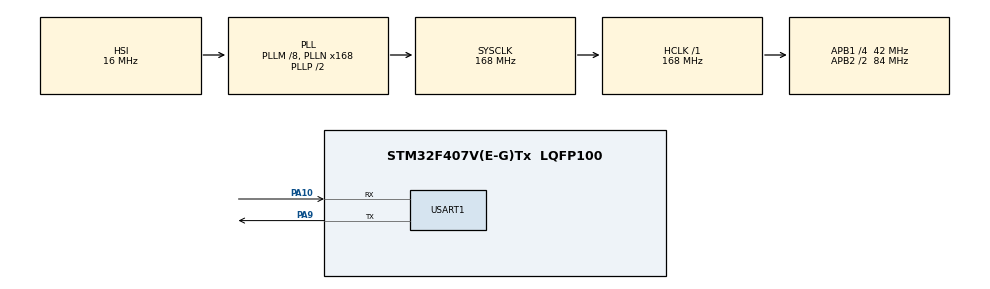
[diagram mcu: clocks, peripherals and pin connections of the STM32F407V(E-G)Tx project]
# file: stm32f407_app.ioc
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Dma.Request0=USART1_RX
Dma.Request1=USART1_TX
Dma.USART1_RX.0.Direction=DMA_PERIPH_TO_MEMORY
Dma.USART1_RX.0.FIFOMode=DMA_FIFOMODE_DISABLE
Dma.USART1_RX.0.Instance=DMA2_Stream2
Dma.USART1_RX.0.MemDataAlignment=DMA_MDATAALIGN_BYTE
Dma.USART1_RX.0.MemInc=DMA_MINC_ENABLE
Dma.USART1_RX.0.Mode=DMA_NORMAL
Dma.USART1_RX.0.PeriphDataAlignment=DMA_PDATAALIGN_BYTE
Dma.USART1_RX.0.PeriphInc=DMA_PINC_DISABLE
Dma.USART1_RX.0.Priority=DMA_PRIORITY_LOW
Dma.USART1_TX.1.Direction=DMA_MEMORY_TO_PERIPH
Dma.USART1_TX.1.FIFOMode=DMA_FIFOMODE_DISABLE
Dma.USART1_TX.1.Instance=DMA2_Stream7
Dma.USART1_TX.1.MemDataAlignment=DMA_MDATAALIGN_BYTE
Dma.USART1_TX.1.MemInc=DMA_MINC_ENABLE
Dma.USART1_TX.1.Mode=DMA_NORMAL
Dma.USART1_TX.1.PeriphDataAlignment=DMA_PDATAALIGN_BYTE
Dma.USART1_TX.1.PeriphInc=DMA_PINC_DISABLE
Dma.USART1_TX.1.Priority=DMA_PRIORITY_LOW
Mcu.Family=STM32F4
Mcu.Name=STM32F407V(E-G)Tx
Mcu.Package=LQFP100
NVIC.DMA2_Stream2_IRQn=true\:0\:0\:false\:false\:true\:false
NVIC.DMA2_Stream7_IRQn=true\:0\:0\:false\:false\:true\:false
NVIC.PriorityGroup=NVIC_PRIORITYGROUP_4
NVIC.USART1_IRQn=true\:0\:0\:false\:false\:true\:true
PA10.Mode=Asynchronous
PA10.Signal=USART1_RX
PA9.Mode=Asynchronous
PA9.Signal=USART1_TX
ProjectManager.HeapSize=0x200
ProjectManager.StackSize=0x400
ProjectManager.TargetToolchain=MDK-ARM V5
RCC.48MHZClocksFreq_Value=84000000
RCC.AHBFreq_Value=168000000
RCC.APB1CLKDivider=RCC_HCLK_DIV4
RCC.APB1Freq_Value=42000000
RCC.APB1TimFreq_Value=84000000
RCC.APB2CLKDivider=RCC_HCLK_DIV2
RCC.APB2Freq_Value=84000000
RCC.APB2TimFreq_Value=168000000
RCC.CortexFreq_Value=168000000
RCC.HCLKFreq_Value=168000000
RCC.HSE_VALUE=25000000
RCC.HSI_VALUE=16000000
RCC.LSE_VALUE=32768
RCC.PLLM=8
RCC.PLLN=168
RCC.SYSCLKFreq_VALUE=168000000
RCC.SYSCLKSource=RCC_SYSCLKSOURCE_PLLCLK
RCC.VCOOutputFreq_Value=336000000
USART1.VirtualMode=VM_ASYNC
board=stm32f407_app

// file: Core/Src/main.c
/**
  ******************************************************************************
  * @file           : main.c
  * @brief          : Main program body
  ******************************************************************************
  ** This notice applies to any and all portions of this file
  * that are not between comment pairs USER CODE BEGIN and
  * USER CODE END. Other portions of this file, whether
  * inserted by the user or by software development tools
  * are owned by their respective copyright owners.
  *
  * COPYRIGHT(c) 2020 STMicroelectronics
  *
  * Redistribution and use in source and binary forms, with or without modification,
  * are permitted provided that the following conditions are met:
  *   1. Redistributions of source code must retain the above copyright notice,
  *      this list of conditions and the following disclaimer.
  *   2. Redistributions in binary form must reproduce the above copyright notice,
  *      this list of conditions and the following disclaimer in the documentation
  *      and/or other materials provided with the distribution.
  *   3. Neither the name of STMicroelectronics nor the names of its contributors
  *      may be used to endorse or promote products derived from this software
  *      without specific prior written permission.
  *
  * THIS SOFTWARE IS PROVIDED BY THE COPYRIGHT HOLDERS AND CONTRIBUTORS "AS IS"
  * AND ANY EXPRESS OR IMPLIED WARRANTIES, INCLUDING, BUT NOT LIMITED TO, THE
  * IMPLIED WARRANTIES OF MERCHANTABILITY AND FITNESS FOR A PARTICULAR PURPOSE ARE
  * DISCLAIMED. IN NO EVENT SHALL THE COPYRIGHT HOLDER OR CONTRIBUTORS BE LIABLE
  * FOR ANY DIRECT, INDIRECT, INCIDENTAL, SPECIAL, EXEMPLARY, OR CONSEQUENTIAL
  * DAMAGES (INCLUDING, BUT NOT LIMITED TO, PROCUREMENT OF SUBSTITUTE GOODS OR
  * SERVICES; LOSS OF USE, DATA, OR PROFITS; OR BUSINESS INTERRUPTION) HOWEVER
  * CAUSED AND ON ANY THEORY OF LIABILITY, WHETHER IN CONTRACT, STRICT LIABILITY,
  * OR TORT (INCLUDING NEGLIGENCE OR OTHERWISE) ARISING IN ANY WAY OUT OF THE USE
  * OF THIS SOFTWARE, EVEN IF ADVISED OF THE POSSIBILITY OF SUCH DAMAGE.
  *
  ******************************************************************************
  */
#include "main.h"
#include "stm32f4xx_hal.h"
#include "dma.h"
#include "usart.h"
#include "gpio.h"

/* USER CODE BEGIN Includes */
#include "flash.h"
/* USER CODE END Includes */

/* USER CODE BEGIN PV */
/* Private variables ---------------------------------------------------------*/

/* USER CODE END PV */

void SystemClock_Config(void);

/* USER CODE BEGIN PFP */
/* Private function prototypes -----------------------------------------------*/

/* USER CODE END PFP */

int main(void)
{
  /* USER CODE BEGIN 1 */
    SCB->VTOR = FLASH_BASE | 0x00020000UL;/* 更改中断向量表地址 */
  /* USER CODE END 1 */

  /* MCU Configuration----------------------------------------------------------*/

  /* Reset of all peripherals, Initializes the Flash interface and the Systick. */
  HAL_Init();

  /* Configure the system clock */
  SystemClock_Config();

  /* Initialize all configured peripherals */
  MX_GPIO_Init();
  MX_DMA_Init();
  MX_USART1_UART_Init();

  /* Infinite loop */
  while (1)
  {

  }

}

void SystemClock_Config(void)
{

  RCC_OscInitTypeDef RCC_OscInitStruct;
  RCC_ClkInitTypeDef RCC_ClkInitStruct;

    /**Configure the main internal regulator output voltage
    */
  __HAL_RCC_PWR_CLK_ENABLE();

  __HAL_PWR_VOLTAGESCALING_CONFIG(PWR_REGULATOR_VOLTAGE_SCALE1);

    /**Initializes the CPU, AHB and APB busses clocks
    */
  RCC_OscInitStruct.OscillatorType = RCC_OSCILLATORTYPE_HSI;
  RCC_OscInitStruct.HSIState = RCC_HSI_ON;
  RCC_OscInitStruct.HSICalibrationValue = 16;
  RCC_OscInitStruct.PLL.PLLState = RCC_PLL_ON;
  RCC_OscInitStruct.PLL.PLLSource = RCC_PLLSOURCE_HSI;
  RCC_OscInitStruct.PLL.PLLM = 8;
  RCC_OscInitStruct.PLL.PLLN = 168;
  RCC_OscInitStruct.PLL.PLLP = RCC_PLLP_DIV2;
  RCC_OscInitStruct.PLL.PLLQ = 4;
  if (HAL_RCC_OscConfig(&RCC_OscInitStruct) != HAL_OK)
  {
    _Error_Handler(__FILE__, __LINE__);
  }

    /**Initializes the CPU, AHB and APB busses clocks
    */
  RCC_ClkInitStruct.ClockType = RCC_CLOCKTYPE_HCLK|RCC_CLOCKTYPE_SYSCLK
                              |RCC_CLOCKTYPE_PCLK1|RCC_CLOCKTYPE_PCLK2;
  RCC_ClkInitStruct.SYSCLKSource = RCC_SYSCLKSOURCE_PLLCLK;
  RCC_ClkInitStruct.AHBCLKDivider = RCC_SYSCLK_DIV1;
  RCC_ClkInitStruct.APB1CLKDivider = RCC_HCLK_DIV4;
  RCC_ClkInitStruct.APB2CLKDivider = RCC_HCLK_DIV2;

  if (HAL_RCC_ClockConfig(&RCC_ClkInitStruct, FLASH_LATENCY_5) != HAL_OK)
  {
    _Error_Handler(__FILE__, __LINE__);
  }

    /**Configure the Systick interrupt time
    */
  HAL_SYSTICK_Config(HAL_RCC_GetHCLKFreq()/1000);

    /**Configure the Systick
    */
  HAL_SYSTICK_CLKSourceConfig(SYSTICK_CLKSOURCE_HCLK);

  /* SysTick_IRQn interrupt configuration */
  HAL_NVIC_SetPriority(SysTick_IRQn, 0, 0);
}

/* USER CODE BEGIN 4 */
// read update status
static uint32_t get_update_status(void) {
	uint32_t status = 0;

	flash_read((APPLICATION_BACKUP_ADDRESS + APPLICATION_SIZE - 4), &status, 1);

	return status;
}

// execute application
static void execute_app(uint32_t app_addr) {
	pFunction JumpToApp;

	if (((*(__IO uint32_t *)app_addr) & 0x2FFE0000) == 0x20000000) {    // 检查栈顶地址是否合法
		/* Jump to user application */
		JumpToApp = (pFunction) *(__IO uint32_t *)(app_addr + 4);       // 用户代码区第二个字为程序开始地址（复位地址）
		/* Initialize user application's Stack Pointer */
		__set_CONTROL(0);
		__set_MSP(*(__IO uint32_t*) app_addr);
		JumpToApp();
	}
}

// update
static void update(void) {
    printf("***********************************\r\n");
    printf("*                                 *\r\n");
    printf("*            BootLoader           *\r\n");
    printf("*                                 *\r\n");
    printf("***********************************\r\n");
    printf("> Choose a startup method......\r\n");

    uint32_t status = get_update_status();
    switch (status) {
        case STARTUP_NORMAL:
            printf("> Normal start......\r\n");
            break;

        case STARTUP_UPDATE:
            printf("> Start update......\r\n");
			flash_move_firmware(APPLICATION_ADDRESS, APPLICATION_BACKUP_ADDRESS, APPLICATION_SIZE);
			printf("> Update down......\r\n");
            break;

        default:
            printf("> Error:%X!!!......\r\n", status);
            break;
    }
    /* 启动程序 */
	printf("> Start up......\r\n\r\n");
	execute_app(APPLICATION_ADDRESS);
}
/* USER CODE END 4 */

void _Error_Handler(char *file, int line)
{
  while(1)
  {
  }
}

/************************ (C) COPYRIGHT STMicroelectronics *****END OF FILE****/
